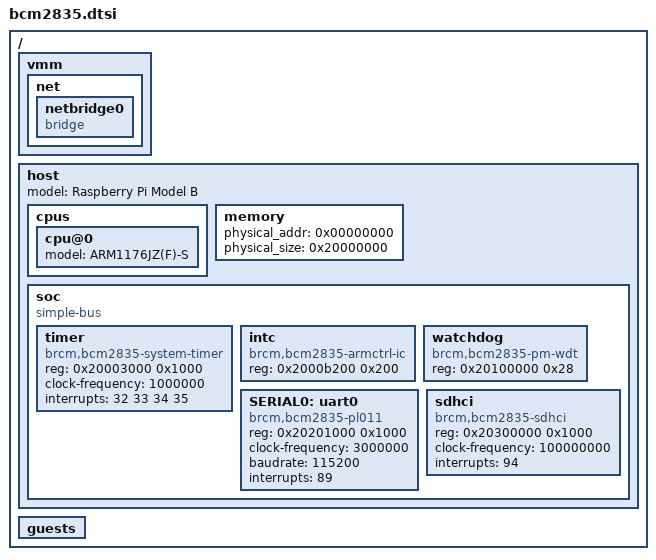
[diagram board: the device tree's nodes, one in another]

/ {
	vmm {
		net {
			netbridge0 {
				device_type = "netswitch";
				compatible = "bridge";
			};
		};
	};

	host {
		#address-cells = <1>;
		#size-cells = <1>;
		model = "Raspberry Pi Model B";
		device_type = "host";
		
		cpus {
			cpu@0 {
				device_type = "cpu";
				model = "ARM1176JZ(F)-S";
			};
		};

		memory {
			physical_addr = <0x00000000>;
			physical_size = <0x20000000>; /* 512 MB */
		};


		soc {
			#address-cells = <1>;
			#size-cells = <1>;
			compatible = "simple-bus";

			timer {
		      		device_type = "timer";
				compatible = "brcm,bcm2835-system-timer";
				reg = <0x20003000 0x1000>;
				clock-frequency = <1000000>;
				interrupts = <32 33 34 35>;
			};

			intc {
		      		device_type = "pic";
				compatible = "brcm,bcm2835-armctrl-ic";
				reg = <0x2000b200 0x200>;
			};

			watchdog {
				compatible = "brcm,bcm2835-pm-wdt";
				reg = <0x20100000 0x28>;
			};

			SERIAL0: uart0 {
		      		device_type = "serial";
		      		compatible = "brcm,bcm2835-pl011", "arm,pl011";
		      		reg = <0x20201000 0x1000>;
				clock-frequency = <3000000>;
		      		baudrate = <115200>;
				interrupts = <89>;
			};

			sdhci {
		      		device_type = "mmc";
				compatible = "brcm,bcm2835-sdhci";
				reg = <0x20300000 0x1000>;
				clock-frequency = <100000000>;
				interrupts = <94>;
			};
		};
	};

	/* Empty guests node */
	guests {
	};
};

/* Add guest templates */
/include/ "../../common/guests/realview-eb-mpcore.dtsi"

